# Cortex_M52 register map
Vendor: Arm Ltd.; Series: ARMv8.1-M Mainline; File version: 1.0.0
CPU: other r0p0, little endian, MPU, FPU, double-precision FPU, DSP, 8 interrupt priority bits
Registers are 32-bit, read-write, reset 0x0 unless marked. A register's access mark holds for its fields unless they carry their own. Offsets are from the block's base; [hi:lo] are bit positions; {n}, {i} and the like mark numbered series; 'fields as' and 'values as' point back to an identical list.

## TPIU — Trace Port Interface Unit: drives the ITM/DWT/ETM trace out through the parallel trace port or the single-wire SWO pin (Manchester or UART/NRZ). ACPR sets the SWO baud rate, SPPR the pin protocol, FFCR the formatter.
Base 0xE0040000
0x00 SSPSR ro — Supported Parallel Port Size Register: bit n-1 set = a trace port width of n bits is supported. Read-only.
  [31:0] SWIDTH — Bit n-1 set = a trace port width of n bits is supported.
0x04 CSPSR — Current Parallel Port Size Register: one-hot, bit n-1 = width n; must be 1 (bit 0) for SWO.
  [31:0] CWIDTH — One-hot current port width: bit n-1 = n bits. 1 = single-bit (SWO).
0x10 ACPR — Asynchronous Clock Prescaler Register: SWO baud rate = TRACECLKIN / (PRESCALER + 1).
  [12:0] PRESCALER — SWO clock divider: baud rate = TRACECLKIN / (PRESCALER + 1). For example 4 MHz SWO from 200 MHz: PRESCALER = 49.
0xF0 SPPR — Selected Pin Protocol Register: parallel trace port, SWO Manchester or SWO NRZ (UART).
  [1:0] TXMODE — Pin protocol: 0 = parallel trace port, 1 = SWO Manchester, 2 = SWO NRZ (UART-like, the common choice), 3 = reserved.
    0=Parallel trace port; 1=SWO_Manchester (Serial wire output, Manchester encoding); 2=SWO_NRZ (Serial wire output, NRZ (UART) encoding)
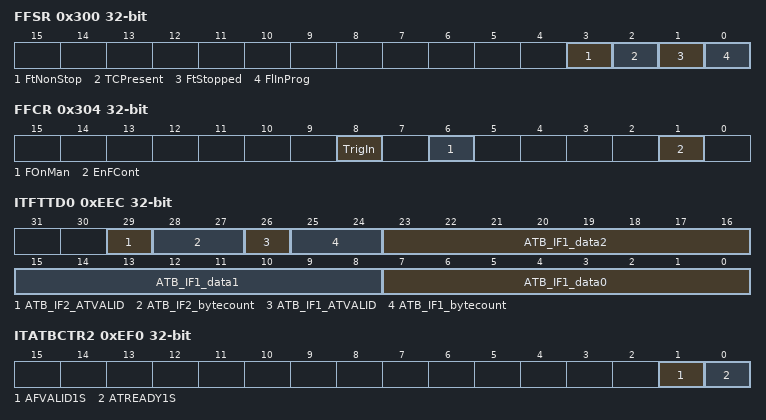
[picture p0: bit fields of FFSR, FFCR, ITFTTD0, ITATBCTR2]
0x300 FFSR ro — Formatter and Flush Status Register.
  [3] FtNonStop — Formatter cannot be stopped (reads 1).
  [2] TCPresent — TRACECTL pin present: 1 = the trace port has a TRACECTL signal.
  [1] FtStopped — Formatter stopped (RAZ on cores whose formatter cannot stop).
  [0] FlInProg — Flush in progress.
0x304 FFCR — Formatter and Flush Control Register: enable continuous formatting (needed when the ETM and ITM share the port), manual flush, trigger indication.
  [8] TrigIn — Indicate a trigger on the TRIGIN input in the formatted stream (reads 1).
  [6] FOnMan — Manual flush: write 1 to flush the formatter FIFO now.
  [1] EnFCont — Enable continuous formatting: 1 = frames are always formatted with source IDs (required when the ETM and ITM share the trace port; must be 0 for ITM-only SWO to get raw ITM packets).
0x308 PSCR — Periodic Synchronization Control Register: how often the formatter inserts synchronization packets.
  [4:0] PSCount — Periodic synchronization: 0 = disabled; else a synchronization sequence is inserted every 2^PSCount bytes (minimum 7 = 128 bytes).
0xEE8 TRIGGER ro — Integration register: the current state of the TRIGIN input.
  [0] TRIGGER — Current state of the TRIGIN input.
0xEEC ITFTTD0 ro — Integration Test FIFO Test Data 0: ATB interface 1 (ETM) data bytes and handshake flags (integration mode).
  [29] ATB_IF2_ATVALID — ATB interface 2 ATVALID.
  [28:27] ATB_IF2_bytecount — ATB interface 2 valid bytes - 1.
  [26] ATB_IF1_ATVALID — ATB interface 1 ATVALID.
  [25:24] ATB_IF1_bytecount — ATB interface 1 valid bytes - 1.
  [23:16] ATB_IF1_data2 — ATB interface 1 data byte 2.
  [15:8] ATB_IF1_data1 — ATB interface 1 data byte 1.
  [7:0] ATB_IF1_data0 — ATB interface 1 data byte 0.
0xEF0 ITATBCTR2 — Integration Test ATB Control 2: ATREADY/AFVALID outputs to the ATB masters (integration mode).
  [1] AFVALID1S — ATB interface 1 AFVALID (integration).
  [0] ATREADY1S — ATB interface 1 ATREADY (integration).
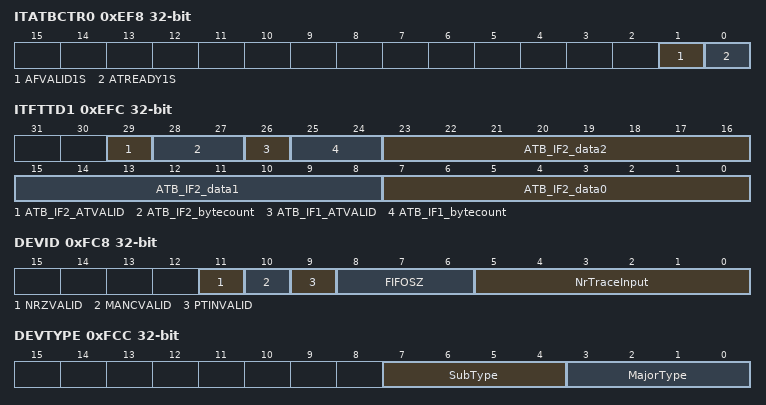
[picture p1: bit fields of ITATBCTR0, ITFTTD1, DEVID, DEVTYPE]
0xEF8 ITATBCTR0 ro — Integration Test ATB Control 0: ATVALID/AFREADY inputs from the ATB masters (integration mode).
  fields as ITATBCTR2
0xEFC ITFTTD1 ro — Integration Test FIFO Test Data 1: ATB interface 2 (ITM) data bytes and handshake flags (integration mode).
  [29] ATB_IF2_ATVALID — ATB interface 2 ATVALID.
  [28:27] ATB_IF2_bytecount — ATB interface 2 valid bytes - 1.
  [26] ATB_IF1_ATVALID — ATB interface 1 ATVALID.
  [25:24] ATB_IF1_bytecount — ATB interface 1 valid bytes - 1.
  [23:16] ATB_IF2_data2 — ATB interface 2 data byte 2.
  [15:8] ATB_IF2_data1 — ATB interface 2 data byte 1.
  [7:0] ATB_IF2_data0 — ATB interface 2 data byte 0.
0xF00 ITCTRL — Integration Mode Control Register.
  [1:0] Mode — Integration mode: 0 = normal operation, 1 = integration test mode (the IT* registers drive/observe the ATB and trace port).
0xFA0 CLAIMSET — Claim Tag Set Register: read = which claim bits are implemented, write 1 = set a claim bit. Lets a debugger and software signal ownership of the TPIU.
  [3:0] SET — Read: 1 = claim bit implemented; write 1 = set the claim bit.
0xFA4 CLAIMCLR — Claim Tag Clear Register: read = current claim tag, write 1 = clear a bit.
  [3:0] CLR — Read: current claim tag; write 1 = clear the claim bit.
0xFC8 DEVID ro — Device Configuration Register: number of trace inputs, FIFO size and which pin protocols are supported. Read-only.
  [11] NRZVALID — 1 = SWO NRZ (UART) encoding is supported.
  [10] MANCVALID — 1 = SWO Manchester encoding is supported.
  [9] PTINVALID — 1 = the parallel trace port is NOT supported (SWO only).
  [8:6] FIFOSZ — Formatter FIFO size, log2 of the number of words (2 = 4 words on Cortex-M33/M55).
  [5:0] NrTraceInput — Number of ATB trace inputs (implementation-defined encoding, see the core TRM; Cortex-M cores with an ETM have two: ETM and ITM).
0xFCC DEVTYPE ro — Device Type Register: 0x11 (trace sink, trace port). Read-only.
  [7:4] SubType — Sub type: 1 = trace port (TPIU).
  [3:0] MajorType — Major type: 1 = trace sink.
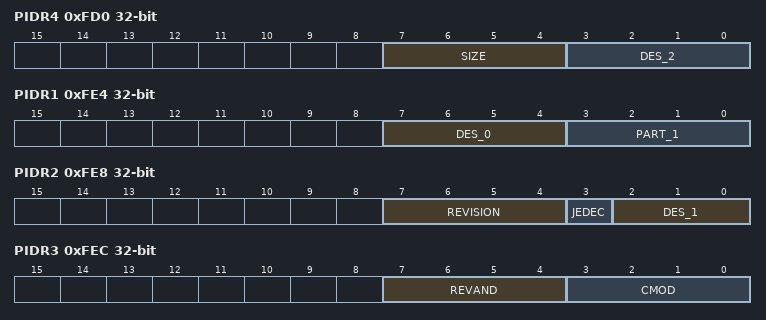
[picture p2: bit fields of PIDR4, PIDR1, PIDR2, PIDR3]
0xFD0 PIDR4 ro — Peripheral Identification Register 4: JEP106 continuation code and component size.
  [7:4] SIZE — Log2 of the number of 4 KB blocks the component occupies (0 = one block).
  [3:0] DES_2 — JEP106 continuation code of the designer (Arm: 0x4).
{0xFC0+4i} PIDR{i} ro (i=5..7) — Peripheral Identification Register {i} (reserved, reads as zero).
0xFE0 PIDR0 ro — Peripheral Identification Register 0: part number bits [7:0].
  [7:0] PART_0 — Part number bits [7:0].
0xFE4 PIDR1 ro — Peripheral Identification Register 1: part number bits [11:8] and designer bits [3:0].
  [7:4] DES_0 — JEP106 identity code bits [3:0] of the designer.
  [3:0] PART_1 — Part number bits [11:8].
0xFE8 PIDR2 ro — Peripheral Identification Register 2: designer bits [6:4], JEDEC flag and revision.
  [7:4] REVISION — Component major revision.
  [3] JEDEC — Always 1: the designer ID is a JEDEC JEP106 code.
  [2:0] DES_1 — JEP106 identity code bits [6:4] of the designer.
0xFEC PIDR3 ro — Peripheral Identification Register 3: customer modified and minor revision.
  [7:4] REVAND — Minor revision (metal fix) number.
  [3:0] CMOD — Customer Modified: 0 if the component has not been modified by the integrator.
0xFF0 CIDR0 ro — Component Identification Register 0: preamble byte 0 (0x0D).
  [7:0] PRMBL_0 — Preamble, reads as 0x0D.
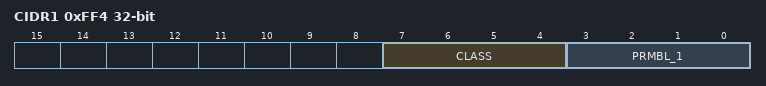
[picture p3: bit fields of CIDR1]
0xFF4 CIDR1 ro — Component Identification Register 1: component class and preamble.
  [7:4] CLASS — Component class: 0x1 ROM table, 0x9 CoreSight component, 0xE generic IP, 0xF CoreLink/PrimeCell.
  [3:0] PRMBL_1 — Preamble, reads as 0x0.
0xFF8 CIDR2 ro — Component Identification Register 2: preamble byte 2 (0x05).
  [7:0] PRMBL_2 — Preamble, reads as 0x05.
0xFFC CIDR3 ro — Component Identification Register 3: preamble byte 3 (0xB1).
  [7:0] PRMBL_3 — Preamble, reads as 0xB1.
